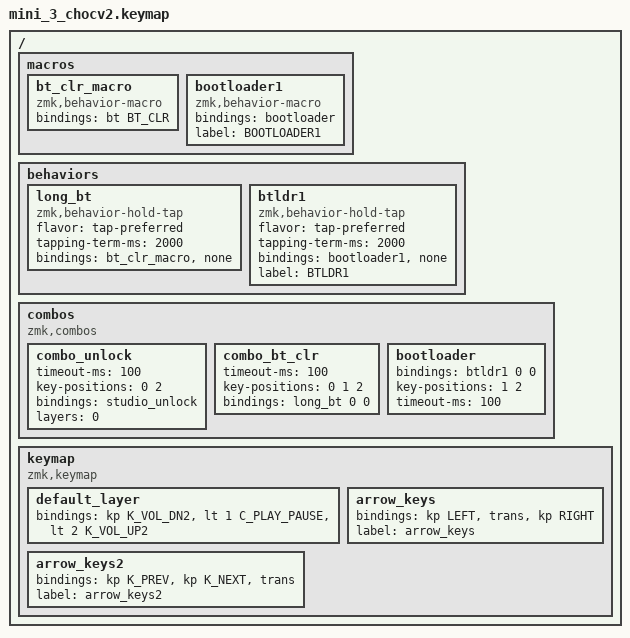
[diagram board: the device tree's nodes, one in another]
#include <behaviors.dtsi>
#include <dt-bindings/zmk/bt.h>
#include <dt-bindings/zmk/keys.h>

/ {
    macros {
        bt_clr_macro: bt_clr_macro {
            compatible = "zmk,behavior-macro";
            #binding-cells = <0>;
            bindings = <&bt BT_CLR>;
        };

        bootloader1: bootloader1 {
            compatible = "zmk,behavior-macro";
            #binding-cells = <0>;
            bindings = <&bootloader>;
            label = "BOOTLOADER1";
        };
    };

    behaviors {
        // Hold for 2 seconds to Clear BT, Tap does nothing

        long_bt: long_bt {
            compatible = "zmk,behavior-hold-tap";
            #binding-cells = <2>;
            flavor = "tap-preferred";
            tapping-term-ms = <2000>;
            bindings = <&bt_clr_macro>, <&none>;
        };

        btldr1: btldr1 {
            compatible = "zmk,behavior-hold-tap";
            #binding-cells = <2>;
            flavor = "tap-preferred";
            tapping-term-ms = <2000>;
            bindings = <&bootloader1>, <&none>;

            label = "BTLDR1";
        };
    };

    combos {
        compatible = "zmk,combos";

        // Top + Bottom = Studio Unlock

        combo_unlock {
            timeout-ms = <100>;
            key-positions = <0 2>;
            bindings = <&studio_unlock>;
            layers = <0>;
        };

        // All 3 Keys = BT Clear (Hold 2s)

        combo_bt_clr {
            timeout-ms = <100>;
            key-positions = <0 1 2>;
            bindings = <&long_bt 0 0>;
        };

        bootloader {
            bindings = <&btldr1 0 0>;
            key-positions = <1 2>;
            timeout-ms = <100>;
        };
    };

    keymap {
        compatible = "zmk,keymap";

        default_layer {
            bindings = <
&kp K_VOL_DN2  &lt 1 C_PLAY_PAUSE  &lt 2 K_VOL_UP2
            >;
        };

        arrow_keys {
            bindings = <
&kp LEFT  &trans  &kp RIGHT
            >;

            label = "arrow_keys";
        };

        arrow_keys2 {
            bindings = <
&kp K_PREV  &kp K_NEXT  &trans
            >;

            label = "arrow_keys2";
        };
    };
};
